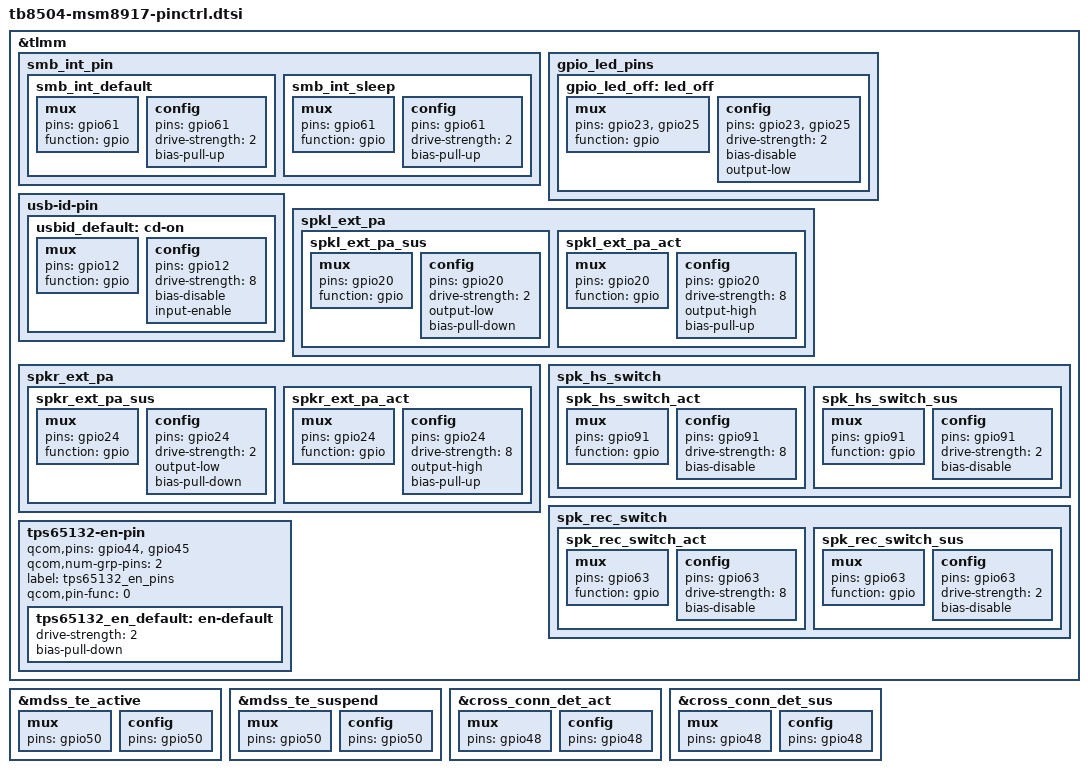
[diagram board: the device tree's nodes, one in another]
&tlmm {

	smb_int_pin {
			smb_int_default: smb_int_default {
				mux {
					pins = "gpio61";
					function ="gpio";
				};
				config {
					pins = "gpio61";
					drive-strength = <2>;   /* 2 MA */
					bias-pull-up;           /* PULL UP*/
				};
			};
			smb_int_sleep: smb_int_sleep {
				mux {
					pins = "gpio61";
					function ="gpio";
				};
				config {
					pins = "gpio61";
					drive-strength = <2>;   /* 2 MA */
					bias-pull-up;           /* PULL UP*/
				};
			};
		};

		gpio_led_pins {
			gpio_led_off: led_off {
				mux {
					pins = "gpio23", "gpio25";
					function = "gpio";
				};

				config {
					pins = "gpio23", "gpio25";
					drive-strength = <2>;
					bias-disable; /* no pullup */
					output-low;
				};
			};
		};

	    usb-id-pin {
			usbid_default: cd-on{
				mux {
					pins = "gpio12";
					function = "gpio";
				};
			   	config {
					pins = "gpio12";
					drive-strength = <8>;
					bias-disable; /* NO pull *///bias-pull-up;
					input-enable;
				};

			};

		};


		spkl_ext_pa {
			spkl_ext_pa_sus: spkl_ext_pa_sus {
				mux {
					pins = "gpio20";
					function = "gpio";
				};
				config {
					pins = "gpio20";
				    drive-strength = <2>;
				    output-low;
				    bias-pull-down;
				   // bias-disable;
				};
			};
			spkl_ext_pa_act: spkl_ext_pa_act {
				mux {
					pins = "gpio20";
					function = "gpio";
				};
				config {
					pins = "gpio20";
				    drive-strength = <8>;
					output-high;
					bias-pull-up;
					//bias-disable;
				};
			};
		};
		spkr_ext_pa {
			spkr_ext_pa_sus: spkr_ext_pa_sus {
				mux {
					pins = "gpio24";
					function = "gpio";
				};
				config {
					pins = "gpio24";
				    drive-strength = <2>;
				    output-low;
				    bias-pull-down;
				 //   bias-disable;
				};
			};
			spkr_ext_pa_act: spkr_ext_pa_act {
				mux {
					pins = "gpio24";
					function = "gpio";
				};
				config {
					pins = "gpio24";
				    drive-strength = <8>;
					output-high;
					bias-pull-up;
					//bias-disable;
				};
			};
		};

		spk_hs_switch {
			spk_hs_switch_act: spk_hs_switch_act {
				mux {
					pins = "gpio91";
					function = "gpio";
				};
				config {
					pins = "gpio91";
				    drive-strength = <8>;
				    bias-disable;
				    //output-high;
				};
			};
			spk_hs_switch_sus: spk_hs_switch_sus {
				mux {
					pins = "gpio91";
					function = "gpio";
				};
				config {
					pins = "gpio91";
					drive-strength = <2>;
					bias-disable;
				};
			};
		};

		spk_rec_switch {
			spk_rec_switch_act: spk_rec_switch_act {
				mux {
					pins = "gpio63";
					function = "gpio";
				};
				config {
			        pins = "gpio63";
					drive-strength = <8>;
					bias-disable;
					//output-high;
				};
			};
			spk_rec_switch_sus: spk_rec_switch_sus {
				mux {
					pins = "gpio63";
					function = "gpio";
				};
				config {
					pins = "gpio63";
					drive-strength = <2>;
					bias-disable;
				};
			};
		};

		tps65132-en-pin {
			qcom,pins = "gpio44", "gpio45";
			qcom,num-grp-pins = <2>;
			label = "tps65132_en_pins";
			qcom,pin-func = <0>;

			tps65132_en_default: en-default {
				drive-strength = <2>;
				bias-pull-down;
			};
		};

};


&mdss_te_active {
	mux {
		 pins = "gpio50";
	};
	config {
		 pins = "gpio50";
	};
};


&mdss_te_suspend {
	mux {
		 pins = "gpio50";
	};
	config {
		 pins = "gpio50";
	};
};

&cross_conn_det_act {
	mux {
		 pins = "gpio48";
	};
	config {
		 pins = "gpio48";
	};
};

&cross_conn_det_sus {
	mux {
		 pins = "gpio48";
	};
	config {
		 pins = "gpio48";
	};
};
